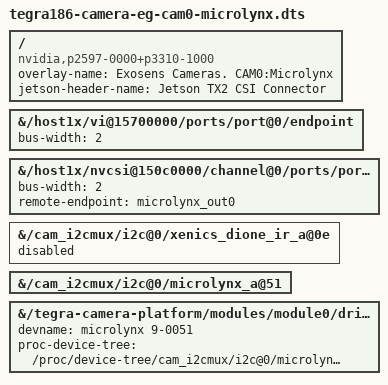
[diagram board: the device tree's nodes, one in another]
// SPDX-License-Identifier: GPL-2.0-only
// SPDX-FileCopyrightText: Copyright (c) 2025, Exosens. All rights reserved.

/dts-v1/;
/plugin/;

/ {
	overlay-name = "Exosens Cameras. CAM0:Microlynx";
	jetson-header-name = "Jetson TX2 CSI Connector";
	compatible = "nvidia,p2597-0000+p3310-1000",
	             "nvidia,p2597-0000+p3489-0000",
	             "nvidia,p2597-0000+p3489-0888",
	             "nvidia,p3509-0000+p3636-0001";

	fragment@10 {
		target-path = "/host1x/vi@15700000/ports/port@0/endpoint";
		__overlay__ {
			bus-width = <2>;
		};
	};

	fragment@11 {
		target-path = "/host1x/nvcsi@150c0000/channel@0/ports/port@0/endpoint@0";
		__overlay__ {
			bus-width = <2>;
			remote-endpoint = <&microlynx_out0>;
		};
	};

	/* Disable Dione */
	fragment@12 {
		target-path = "/cam_i2cmux/i2c@0/xenics_dione_ir_a@0e";
		__overlay__ {
			status = "disabled";
		};
	};

	/* Enable Microlynx */
	fragment@13 {
		target-path = "/cam_i2cmux/i2c@0/microlynx_a@51";
		__overlay__ {
			status = "okay";
		};
	};

	fragment@21 {
		target-path = "/tegra-camera-platform/modules/module0/drivernode0";
		__overlay__ {
			devname = "microlynx 9-0051";
			proc-device-tree = "/proc/device-tree/cam_i2cmux/i2c@0/microlynx_a@51";
		};
	};
};
